# STM32WB10CCU6 register map
File version: 1.0
Registers are 32-bit, access not given, reset 0x0 unless marked. A register's access mark holds for its fields unless they carry their own. Offsets are from the block's base; [hi:lo] are bit positions; {n}, {i} and the like mark numbered series.

## GPIOH
Base 0x48001C00
0x00 MODER
  [7:6] MODE3
0x04 OTYPER
  [3] OT3
0x08 OSPEEDR
  [7:6] OSPEED3
0x0C PUPDR
  [7:6] PUPD3
0x10 IDR
  [3] ID3
0x14 ODR
  [3] OD3
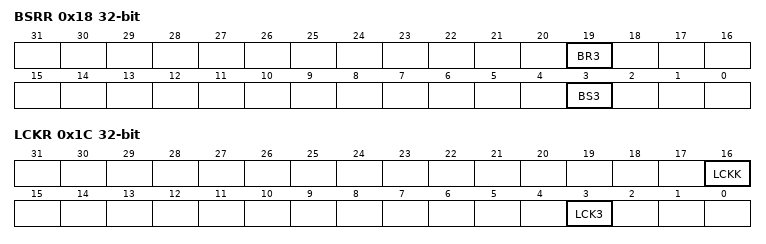
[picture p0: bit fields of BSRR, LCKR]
0x18 BSRR
  [19] BR3, [3] BS3
0x1C LCKR
  [16] LCKK, [3] LCK3
0x20 AFRL
  [15:12] AFSEL3
0x24 AFRH
0x28 BRR
  [3] BR3

## PWR
Base 0x58000400
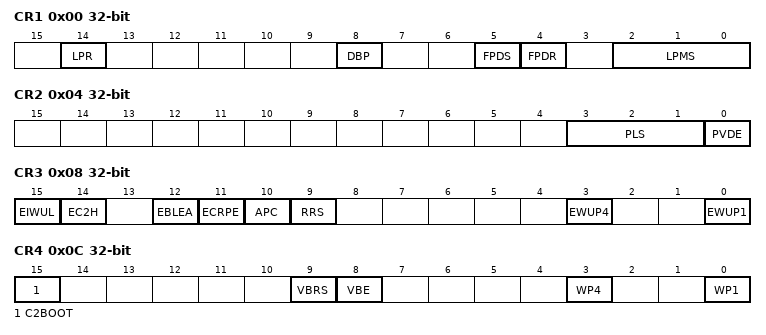
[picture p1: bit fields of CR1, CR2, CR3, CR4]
0x00 CR1
  [14] LPR, [8] DBP, [5] FPDS, [4] FPDR, [2:0] LPMS
0x04 CR2
  [3:1] PLS, [0] PVDE
0x08 CR3
  [15] EIWUL, [14] EC2H, [12] EBLEA, [11] ECRPE, [10] APC, [9] RRS, [3] EWUP4, [0] EWUP1
0x0C CR4
  [15] C2BOOT, [9] VBRS, [8] VBE, [3] WP4, [0] WP1
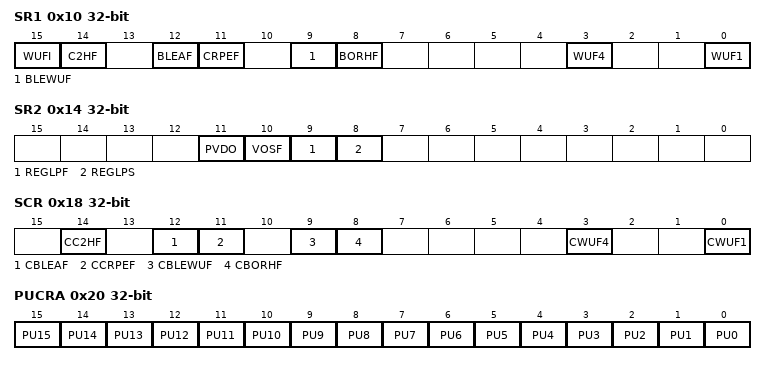
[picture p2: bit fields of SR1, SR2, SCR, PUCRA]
0x10 SR1
  [15] WUFI, [14] C2HF, [12] BLEAF, [11] CRPEF, [9] BLEWUF, [8] BORHF, [3] WUF4, [0] WUF1
0x14 SR2
  [11] PVDO, [10] VOSF, [9] REGLPF, [8] REGLPS
0x18 SCR
  [14] CC2HF, [12] CBLEAF, [11] CCRPEF, [9] CBLEWUF, [8] CBORHF, [3] CWUF4, [0] CWUF1
0x20 PUCRA
  [n] PU{n} (n=0..15)
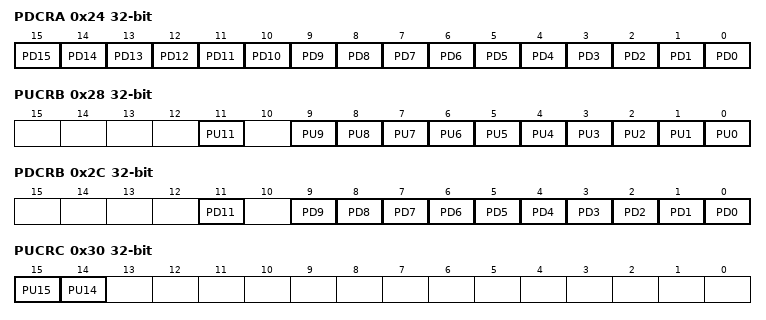
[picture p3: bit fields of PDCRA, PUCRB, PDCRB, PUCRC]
0x24 PDCRA
  [n] PD{n} (n=0..15)
0x28 PUCRB
  [11] PU11, [n] PU{n} (n=0..9)
0x2C PDCRB
  [11] PD11, [n] PD{n} (n=0..9)
0x30 PUCRC
  [15] PU15, [14] PU14
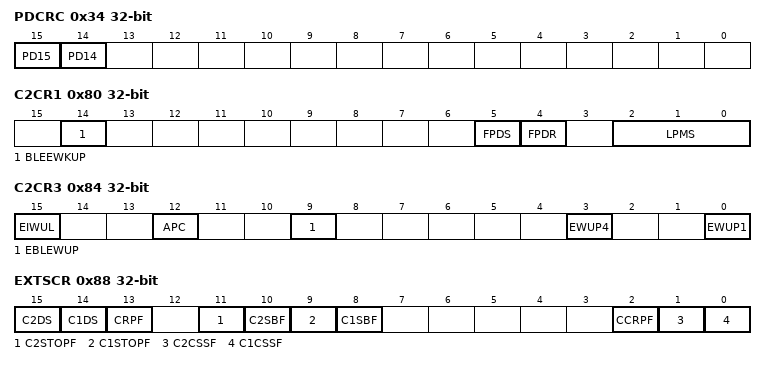
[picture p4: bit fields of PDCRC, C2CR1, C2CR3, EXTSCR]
0x34 PDCRC
  [15] PD15, [14] PD14
0x40 PUCRE
  [4] PU4
0x44 PDCRE
  [4] PD4
0x58 PUCRH
  [3] PU3
0x5C PDCRH
  [3] PD3
0x80 C2CR1
  [14] BLEEWKUP, [5] FPDS, [4] FPDR, [2:0] LPMS
0x84 C2CR3
  [15] EIWUL, [12] APC, [9] EBLEWUP, [3] EWUP4, [0] EWUP1
0x88 EXTSCR
  [15] C2DS, [14] C1DS, [13] CRPF, [11] C2STOPF, [10] C2SBF, [9] C1STOPF, [8] C1SBF, [2] CCRPF, [1] C2CSSF, [0] C1CSSF

## EXTI
Base 0x58000800
0x00 RTSR1
  [20:0] RT
0x04 FTSR1
  [20:0] FT
0x08 SWIER1
  [20:0] SWI
0x0C PR1
  [20:0] PIF
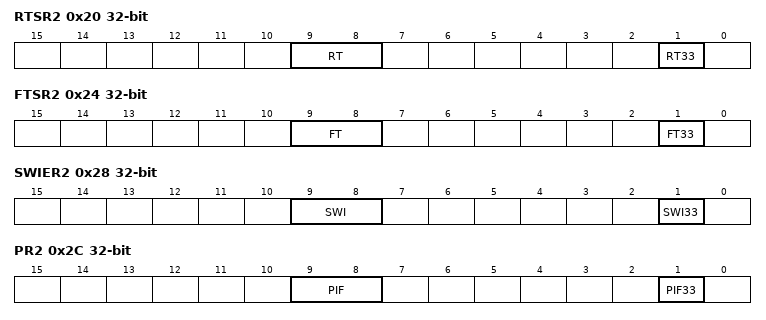
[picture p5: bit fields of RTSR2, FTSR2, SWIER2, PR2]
0x20 RTSR2
  [9:8] RT, [1] RT33
0x24 FTSR2
  [9:8] FT, [1] FT33
0x28 SWIER2
  [9:8] SWI, [1] SWI33
0x2C PR2
  [9:8] PIF, [1] PIF33
0x80 IMR1
  [24] IM24, [22] IM22, [30:0] IM
0x84 EMR1
  [19:0] EM
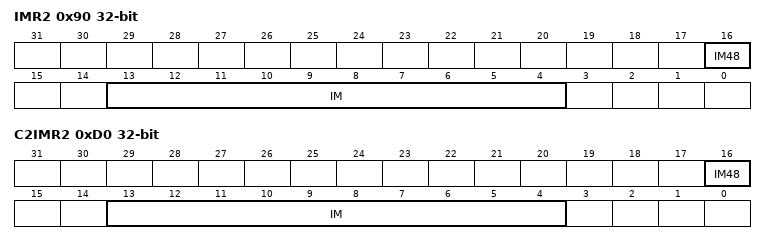
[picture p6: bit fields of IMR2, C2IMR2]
0x90 IMR2
  [16] IM48, [13:4] IM
0x94 EMR2
  [9:8] EM
0xC0 C2IMR1
  [25] IM25, [22] IM22, [30:0] IM
0xC4 C2EMR1
  [19:0] EM
0xD0 C2IMR2
  [16] IM48, [13:4] IM
0xD4 C2EMR2
  [9:8] EM

## IPCC
Base 0x58000C00
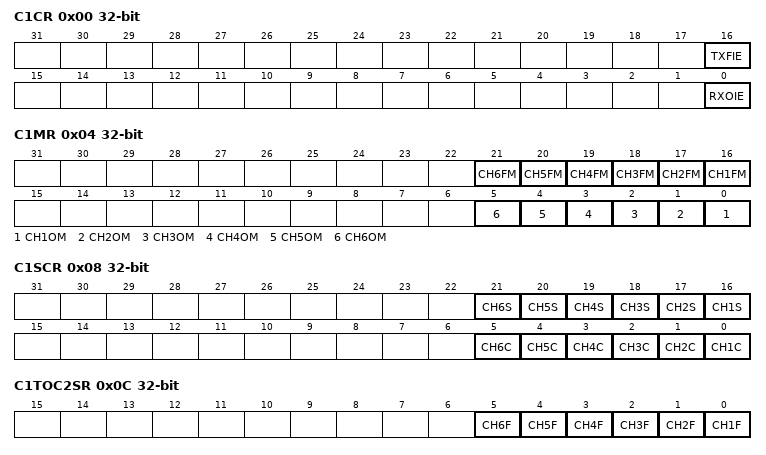
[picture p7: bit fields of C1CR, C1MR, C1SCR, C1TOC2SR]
0x00 C1CR
  [16] TXFIE, [0] RXOIE
0x04 C1MR
  [n+15] CH{n}FM (n=1..6), [n-1] CH{n}OM (n=1..6)
0x08 C1SCR
  [n+15] CH{n}S (n=1..6), [n-1] CH{n}C (n=1..6)
0x0C C1TOC2SR
  [n-1] CH{n}F (n=1..6)
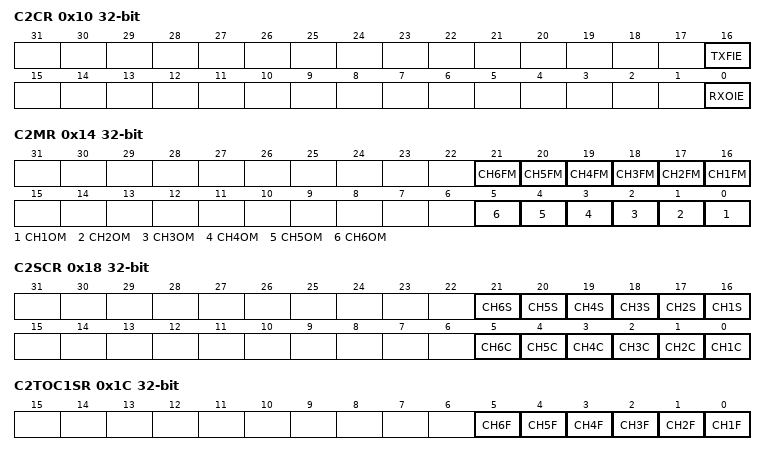
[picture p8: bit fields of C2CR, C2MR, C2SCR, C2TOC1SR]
0x10 C2CR
  [16] TXFIE, [0] RXOIE
0x14 C2MR
  [n+15] CH{n}FM (n=1..6), [n-1] CH{n}OM (n=1..6)
0x18 C2SCR
  [n+15] CH{n}S (n=1..6), [n-1] CH{n}C (n=1..6)
0x1C C2TOC1SR
  [n-1] CH{n}F (n=1..6)

## TRNG
Base 0x58001000
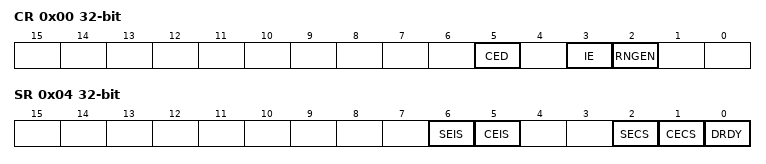
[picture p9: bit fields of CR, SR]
0x00 CR
  [5] CED, [3] IE, [2] RNGEN
0x04 SR
  [6] SEIS, [5] CEIS, [2] SECS, [1] CECS, [0] DRDY
0x08 DR
  [31:0] RNDATA

## HSEM
Base 0x58001400
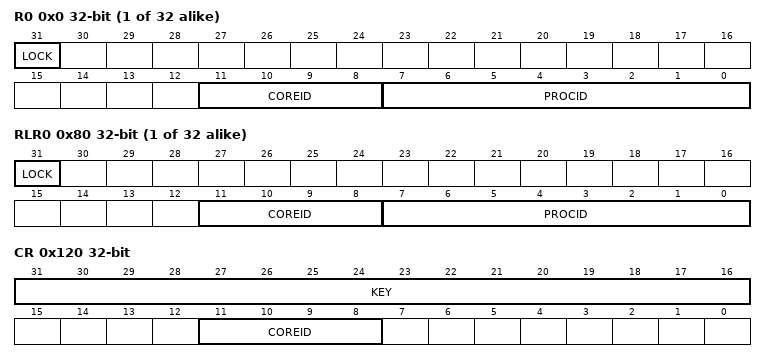
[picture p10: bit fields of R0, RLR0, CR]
{0x0+4i} R{i} (i=0..31)
  [31] LOCK, [11:8] COREID, [7:0] PROCID
{0x80+4i} RLR{i} (i=0..31)
  [31] LOCK, [11:8] COREID, [7:0] PROCID
0x100 C1IER
  [31:0] ISE
0x104 C1ICR
  [31:0] ISC
0x108 C1ISR
  [31:0] ISF
0x10C C1MISR
  [31:0] MISF
0x110 C2IER
  [31:0] ISE
0x114 C2ICR
  [31:0] ISC
0x118 C2ISR
  [31:0] ISF
0x11C C2MISR
  [31:0] MISF
0x120 CR
  [31:16] KEY, [11:8] COREID
0x124 KEYR
  [31:16] KEY

## AES2
Base 0x58001800
0x00 CR
  [23:20] NPBLB, [18] KEYSIZE, [14:13] GCMPH, [12] DMAOUTEN, [11] DMAINEN, [10] ERRIE, [9] CCFIE, [8] ERRC, [7] CCFC, [16:5] CHMOD, [4:3] MODE, [2:1] DATATYPE, [0] EN
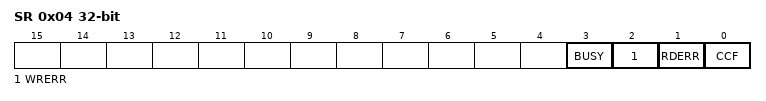
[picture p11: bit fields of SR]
0x04 SR
  [3] BUSY, [2] WRERR, [1] RDERR, [0] CCF
0x08 DINR
  [31:0] DIN
0x0C DOUTR
  [31:0] DOUT
{0x10+4i} KEYR{i} (i=0..3)
  [31:0] KEY
{0x20+4i} IVR{i} (i=0..3)
  [31:0] IVI
{0x20+4i} KEYR{i} (i=4..7)
  [31:0] KEY
{0x40+4i} SUSP{i}R (i=0..7)
  [31:0] SUSP

## PKA
Base 0x58002000
Same registers: PKARAM 0x58002400
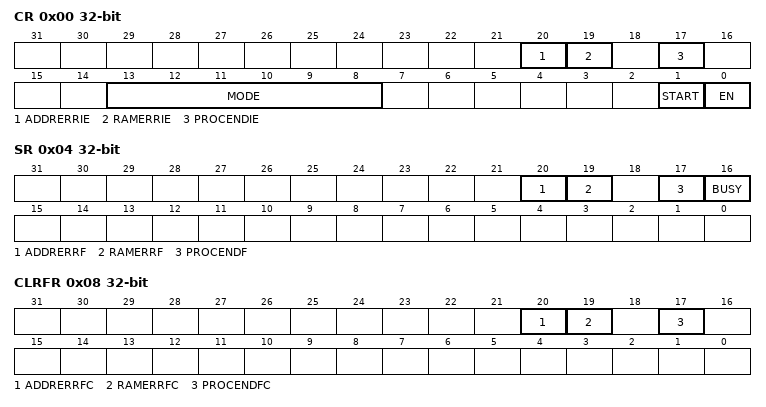
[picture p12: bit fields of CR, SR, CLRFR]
0x00 CR
  [20] ADDRERRIE, [19] RAMERRIE, [17] PROCENDIE, [13:8] MODE, [1] START, [0] EN
0x04 SR
  [20] ADDRERRF, [19] RAMERRF, [17] PROCENDF, [16] BUSY
0x08 CLRFR
  [20] ADDRERRFC, [19] RAMERRFC, [17] PROCENDFC
